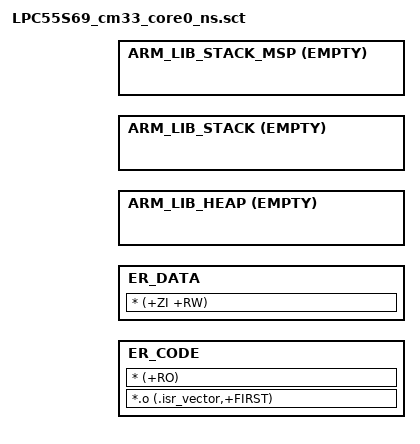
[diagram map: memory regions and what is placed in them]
#! armclang --target=arm-arm-none-eabi -march=armv8-m.main -E -xc

/*
 * Copyright (c) 2018-2019 Arm Limited. All rights reserved.
 *
 * Licensed under the Apache License, Version 2.0 (the "License");
 * you may not use this file except in compliance with the License.
 * You may obtain a copy of the License at
 *
 *     http://www.apache.org/licenses/LICENSE-2.0
 *
 * Unless required by applicable law or agreed to in writing, software
 * distributed under the License is distributed on an "AS IS" BASIS,
 * WITHOUT WARRANTIES OR CONDITIONS OF ANY KIND, either express or implied.
 * See the License for the specific language governing permissions and
 * limitations under the License.
 */

#include "/../../../partition/region_defs.h"

LR_CODE NS_CODE_START {
    ER_CODE NS_CODE_START NS_CODE_SIZE {
        *.o (.isr_vector,+FIRST)
        * (+RO)
    }

    ER_DATA NS_DATA_START NS_DATA_SIZE-NS_MSP_STACK_SIZE-NS_PSP_STACK_SIZE-NS_HEAP_SIZE {
        * (+ZI +RW)
    }
    
    ARM_LIB_HEAP +0 EMPTY NS_HEAP_SIZE {    ; Heap region growing up?
    }
    ARM_LIB_STACK NS_DATA_START+NS_DATA_SIZE EMPTY -NS_PSP_STACK_SIZE { ; Stack region growing down
    }
    ARM_LIB_STACK_MSP NS_DATA_START+NS_DATA_SIZE-NS_PSP_STACK_SIZE EMPTY -NS_MSP_STACK_SIZE { ; Stack region growing down
    }
}
